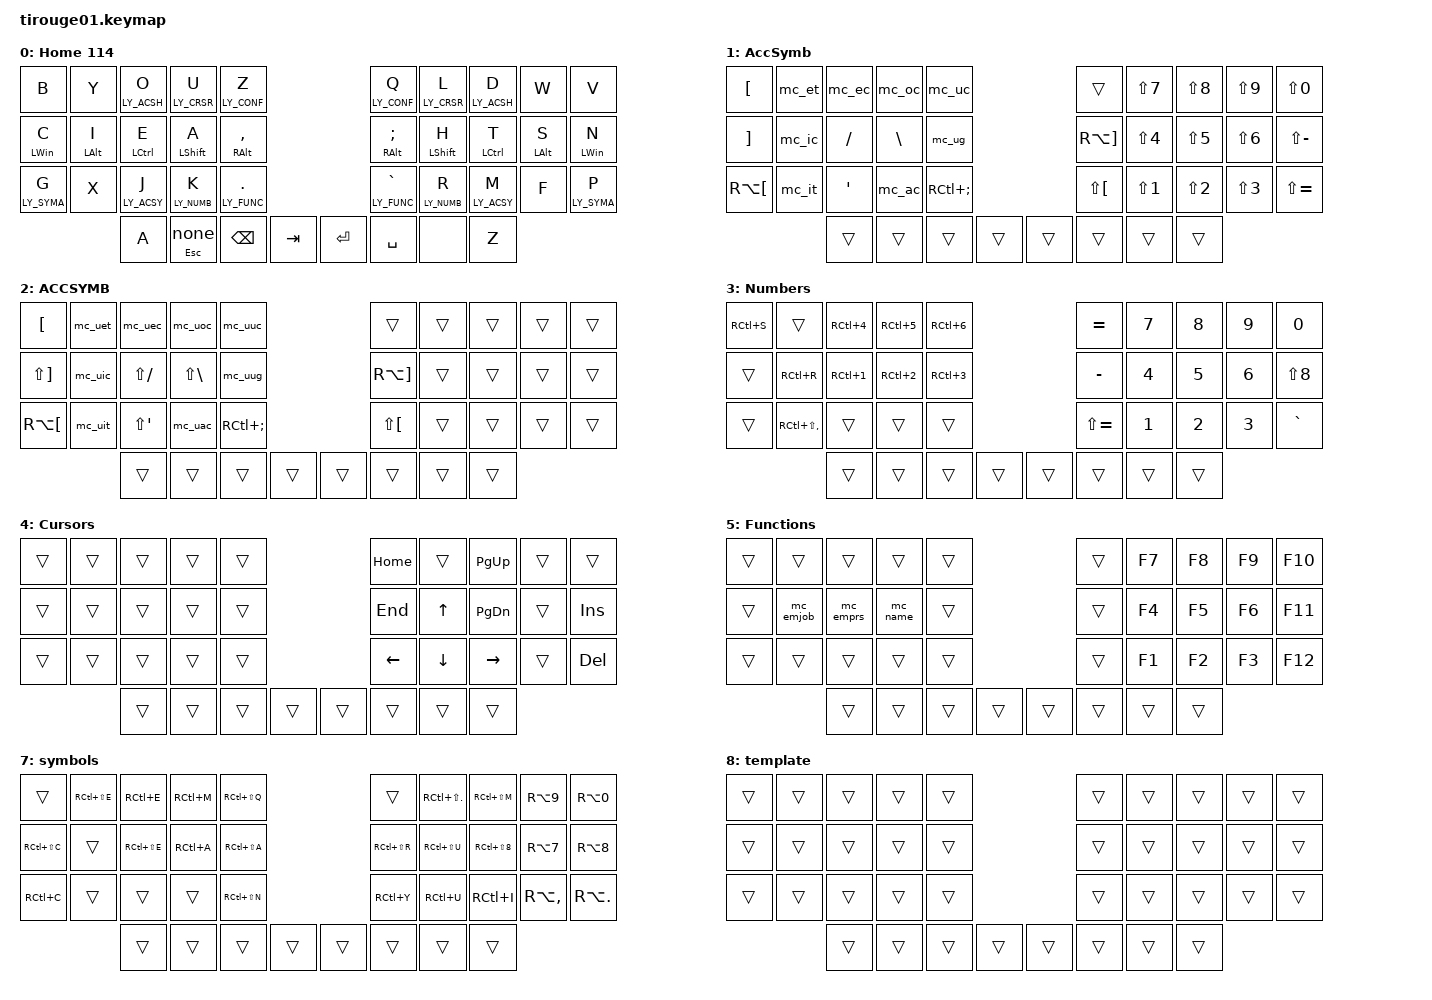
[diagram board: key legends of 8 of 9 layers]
/*
 * Copyright (c) 2022 The ZMK Contributors
 *
 * SPDX-License-Identifier: MIT
 */

#include <behaviors.dtsi>
#include <dt-bindings/zmk/keys.h>
#include <dt-bindings/zmk/bt.h>
#include <dt-bindings/zmk/outputs.h>

#define LY_DEFT 0 // Default layer.
#define LY_ACSY 1 // Accent & Symbols layer.
#define LY_ACSH 2 // Accent & Symbols shifted layer.
#define LY_NUMB 3 // Numbers layer.
#define LY_CRSR 4 // Cursor layer.
#define LY_FUNC 5 // Function layer.
#define LY_CONF 6 // Configuration layer.
#define LY_SYMA 7 // Symbols Group A layer
#define LY_TMPL 8 // Template layer.

#define TIMING_CONFIG 990 // Timing for configuration layer for the "hold/layer" related actions.
#define TIMING_PINKY  220 // Timing for pinky finger for the "hold/layer" related actions.
#define TIMING_RING   220 // Timing for ring finger for the "hold/layer" related actions.
#define TIMING_MIDDLE 200 // Timing for middle finger for the "hold/layer" related actions.
#define TIMING_INDEX  200 // Timing for index finger for the "hold/layer" related actions.
#define TIMING_THUMB  400 // Timing for thumb finger on which I am accidentally pressing too often.

// https://zmk.dev/docs/keymaps/behaviors/sticky-layer
//
// ...
// By default, sticky layers stay pressed for a second if you don't press any other key.
// You can configure this with the release-after-ms setting (see below).
// ...
&sl {
    release-after-ms = <5000>;
    ignore-modifiers;
};


/ {
    behaviors {
        ht_p: hold_tap_pinky_finger {
            compatible = "zmk,behavior-hold-tap";
            #binding-cells = <2>;
            flavor = "balanced";
            tapping-term-ms = <TIMING_PINKY>;
            quick-tap-ms = <175>;
            require-prior-idle-ms = <150>;
            bindings = <&kp>, <&kp>;
        };

        ht_r: hold_tap_ring_finger {
            compatible = "zmk,behavior-hold-tap";
            #binding-cells = <2>;
            flavor = "balanced";
            tapping-term-ms = <TIMING_RING>;
            quick-tap-ms = <175>;
            require-prior-idle-ms = <150>;
            bindings = <&kp>, <&kp>;
        };

        ht_m: hold_tap_middle_finger {
            compatible = "zmk,behavior-hold-tap";
            #binding-cells = <2>;
            flavor = "balanced";
            tapping-term-ms = <TIMING_MIDDLE>;
            quick-tap-ms = <175>;
            require-prior-idle-ms = <150>;
            bindings = <&kp>, <&kp>;
        };

        ht_i: hold_tap_index_finger {
            compatible = "zmk,behavior-hold-tap";
            #binding-cells = <2>;
            flavor = "balanced";
            tapping-term-ms = <TIMING_INDEX>;
            quick-tap-ms = <175>;
            require-prior-idle-ms = <150>;
            bindings = <&kp>, <&kp>;
        };

        ht_t: hold_tap_thumb_finger {
            compatible = "zmk,behavior-hold-tap";
            #binding-cells = <2>;
            flavor = "balanced";
            tapping-term-ms =  <TIMING_THUMB>;
            quick-tap-ms = <175>;
            require-prior-idle-ms = <150>;
            bindings = <&kp>, <&none>;
        };

        lt_c: layer_tap_config_long_timing {
            compatible = "zmk,behavior-hold-tap";
            #binding-cells = <2>;
            flavor = "balanced";
            tapping-term-ms = <TIMING_CONFIG>;
            quick-tap-ms = <175>;
            require-prior-idle-ms = <150>;
            bindings = <&mo>, <&kp>;
        };

        lt_p: layer_tap_pinky_finger {
            compatible = "zmk,behavior-hold-tap";
            #binding-cells = <2>;
            flavor = "balanced";
            tapping-term-ms = <TIMING_PINKY>;
            quick-tap-ms = <175>;
            require-prior-idle-ms = <150>;
            bindings = <&mo>, <&kp>;
        };

        lt_r: layer_tap_ring_finger {
            compatible = "zmk,behavior-hold-tap";
            #binding-cells = <2>;
            flavor = "balanced";
            tapping-term-ms = <TIMING_RING>;
            quick-tap-ms = <175>;
            require-prior-idle-ms = <150>;
            bindings = <&mo>, <&kp>;
        };

        lt_m: layer_tap_middle_finger {
            compatible = "zmk,behavior-hold-tap";
            #binding-cells = <2>;
            flavor = "balanced";
            tapping-term-ms = <TIMING_MIDDLE>;
            quick-tap-ms = <175>;
            require-prior-idle-ms = <150>;
            bindings = <&mo>, <&kp>;
        };

        lt_i: layer_tap_index_finger {
            compatible = "zmk,behavior-hold-tap";
            #binding-cells = <2>;
            flavor = "balanced";
            tapping-term-ms = <TIMING_INDEX>;
            quick-tap-ms = <175>;
            require-prior-idle-ms = <150>;
            bindings = <&mo>, <&kp>;
        };

        tg_p: layer_toggle_pinky_finger {
            compatible = "zmk,behavior-hold-tap";
            #binding-cells = <2>;
            flavor = "balanced";
            tapping-term-ms = <TIMING_PINKY>;
            quick-tap-ms = <175>;
            require-prior-idle-ms = <150>;
            bindings = <&tog>, <&kp>;
        };

        tg_r: layer_toggle_ring_finger {
            compatible = "zmk,behavior-hold-tap";
            #binding-cells = <2>;
            flavor = "balanced";
            tapping-term-ms = <TIMING_RING>;
            quick-tap-ms = <175>;
            require-prior-idle-ms = <150>;
            bindings = <&tog>, <&kp>;
        };

        tg_m: layer_toggle_middle_finger {
            compatible = "zmk,behavior-hold-tap";
            #binding-cells = <2>;
            flavor = "balanced";
            tapping-term-ms = <TIMING_MIDDLE>;
            quick-tap-ms = <175>;
            require-prior-idle-ms = <150>;
            bindings = <&tog>, <&kp>;
        };

        tg_i: layer_toggle_index_finger {
            compatible = "zmk,behavior-hold-tap";
            #binding-cells = <2>;
            flavor = "balanced";
            tapping-term-ms = <TIMING_INDEX>;
            quick-tap-ms = <175>;
            require-prior-idle-ms = <150>;
            bindings = <&tog>, <&kp>;
        };

        st_i: layer_sticky_index_finger {
            compatible = "zmk,behavior-hold-tap";
            #binding-cells = <2>;
            flavor = "balanced";
            tapping-term-ms = <TIMING_INDEX>;
            quick-tap-ms = <175>;
            require-prior-idle-ms = <150>;
            bindings = <&sl>, <&kp>;
        };

        // If you wish to ensure that a layer is toggled on or off specifically,
        // rather than switching between the two states,
        // then you can do so with the toggle-mode property.
        // Define a new behavior and assign "on" or "off" to toggle-mode.
        // https://zmk.dev/docs/keymaps/behaviors/layers#configuration
        gltog_on: toggle_layer_on_only {
            compatible = "zmk,behavior-toggle-layer";
            #binding-cells = <1>;
            display-name = "Toggle Layer On";
            toggle-mode = "on";
        };

        gltog_off: toggle_layer_off_only {
            compatible = "zmk,behavior-toggle-layer";
            #binding-cells = <1>;
            display-name = "Toggle Layer Off";
            toggle-mode = "off";
        };

        // A tap-dance key invokes a different behavior (e.g. kp) corresponding to how many times it is pressed.
        // https://zmk.dev/docs/keymaps/behaviors/tap-dance
        td_menus: tap_dance_popup_main_menus {
            compatible = "zmk,behavior-tap-dance";
            #binding-cells = <0>;
            tapping-term-ms = <200>;
            bindings = <&mc_contextcursor>, <&mc_mainmenucursor>;
        };
    };

    macros {
        // Macro to open the context menu, scroll to the first item and switch to the cursor layer.
        mc_contextcursor: macro_contextcursor {
            compatible = "zmk,behavior-macro";
            #binding-cells = <0>;
            wait-ms = <10>;
            bindings = <&kp K_CONTEXT_MENU &kp DOWN &gltog_on LY_CRSR>;
        };

        // Macro to open the main menu, scroll to the first item and switch to the cursor layer.
        mc_mainmenucursor: macro_mainmenucursor {
            compatible = "zmk,behavior-macro";
            #binding-cells = <0>;
            wait-ms = <10>;
            bindings = <&kp LALT &kp DOWN &gltog_on LY_CRSR>;
        };

        // Macro to exit the cursor layer and press enter to launch the selected item.
        mc_enterexitpopup: macro_enterexitpopup {
            compatible = "zmk,behavior-macro";
            #binding-cells = <0>;
            wait-ms = <10>;
            bindings = <&gltog_off LY_CRSR &kp KP_ENTER>;
        };

        // â
        mc_ac: macro_a_circumflex {
            compatible = "zmk,behavior-macro";
            #binding-cells = <0>;
            wait-ms = <10>;
            bindings = <&kp LBKT &kp A>;
        };

        // ê
        mc_ec: macro_e_circumflex {
            compatible = "zmk,behavior-macro";
            #binding-cells = <0>;
            wait-ms = <10>;
            bindings = <&kp LBKT &kp E>;
        };

        // ë
        mc_et: macro_e_trema {
            compatible = "zmk,behavior-macro";
            #binding-cells = <0>;
            wait-ms = <10>;
            bindings = <&kp LS(LBKT) &kp E>;
        };

        // î
        mc_ic: macro_i_circumflex {
            compatible = "zmk,behavior-macro";
            #binding-cells = <0>;
            wait-ms = <10>;
            bindings = <&kp LBKT &kp I>;
        };

        // ï
        mc_it: macro_i_trema {
            compatible = "zmk,behavior-macro";
            #binding-cells = <0>;
            wait-ms = <10>;
            bindings = <&kp LS(LBKT) &kp I>;
        };

        // í
        mc_ia: macro_i_acute {
            compatible = "zmk,behavior-macro";
            #binding-cells = <0>;
            wait-ms = <10>;
            bindings = <&kp RC(SEMI) &kp I>;
        };

        // ú
        mc_ua: macro_u_acute {
            compatible = "zmk,behavior-macro";
            #binding-cells = <0>;
            wait-ms = <10>;
            bindings = <&kp RC(SEMI) &kp U>;
        };

        // ô
        mc_oc: macro_o_circumflex {
            compatible = "zmk,behavior-macro";
            #binding-cells = <0>;
            wait-ms = <10>;
            bindings = <&kp LBKT &kp O>;
        };

        // ù
        mc_ug: macro_u_grave {
            compatible = "zmk,behavior-macro";
            #binding-cells = <0>;
            wait-ms = <10>;
            bindings = <&kp RA(LBKT) &kp U>;
        };

        // û
        mc_uc: macro_u_circumflex {
            compatible = "zmk,behavior-macro";
            #binding-cells = <0>;
            wait-ms = <10>;
            bindings = <&kp LBKT &kp U>;
        };

        // ü
        mc_ut: macro_u_trema {
            compatible = "zmk,behavior-macro";
            #binding-cells = <0>;
            wait-ms = <10>;
            bindings = <&kp LS(LBKT) &kp U>;
        };

        // Â
        mc_uac: macro_ua_circumflex {
            compatible = "zmk,behavior-macro";
            #binding-cells = <0>;
            wait-ms = <10>;
            bindings = <&kp LBKT &kp LS(A)>;
        };

        // Ê
        mc_uec: macro_ue_circumflex {
            compatible = "zmk,behavior-macro";
            #binding-cells = <0>;
            wait-ms = <10>;
            bindings = <&kp LBKT &kp LS(E)>;
        };

        // Ë
        mc_uet: macro_ue_trema {
            compatible = "zmk,behavior-macro";
            #binding-cells = <0>;
            wait-ms = <10>;
            bindings = <&kp LS(LBKT) &kp LS(E)>;
        };

        // Î
        mc_uic: macro_ui_circumflex {
            compatible = "zmk,behavior-macro";
            #binding-cells = <0>;
            wait-ms = <10>;
            bindings = <&kp LBKT &kp LS(I)>;
        };

        // Ï
        mc_uit: macro_ui_trema {
            compatible = "zmk,behavior-macro";
            #binding-cells = <0>;
            wait-ms = <10>;
            bindings = <&kp LS(LBKT) &kp LS(I)>;
        };

        // Í
        mc_uia: macro_ui_acute {
            compatible = "zmk,behavior-macro";
            #binding-cells = <0>;
            wait-ms = <10>;
            bindings = <&kp RC(SEMI) &kp LS(I)>;
        };

        // Ú
        mc_uua: macro_uu_acute {
            compatible = "zmk,behavior-macro";
            #binding-cells = <0>;
            wait-ms = <10>;
            bindings = <&kp RC(SEMI) &kp LS(U)>;
        };

        // Ô
        mc_uoc: macro_uo_circumflex {
            compatible = "zmk,behavior-macro";
            #binding-cells = <0>;
            wait-ms = <10>;
            bindings = <&kp LBKT &kp LS(O)>;
        };

        // Ù
        mc_uug: macro_uu_grave {
            compatible = "zmk,behavior-macro";
            #binding-cells = <0>;
            wait-ms = <10>;
            bindings = <&kp RA(LBKT) &kp LS(U)>;
        };

        // Û
        mc_uuc: macro_uu_circumflex {
            compatible = "zmk,behavior-macro";
            #binding-cells = <0>;
            wait-ms = <10>;
            bindings = <&kp LBKT &kp LS(U)>;
        };

        // Ü
        mc_uut: macro_uu_trema {
            compatible = "zmk,behavior-macro";
            #binding-cells = <0>;
            wait-ms = <10>;
            bindings = <&kp LS(LBKT) &kp LS(U)>;
        };

        mc_emprs: macro_email_perso {
            compatible = "zmk,behavior-macro";
            #binding-cells = <0>;
            wait-ms = <10>;
            bindings = <
                &kp D &kp E &kp N &kp I &kp S
                &kp DOT
                &kp B &kp I &kp S &kp S &kp O &kp N
                &kp AT
                &kp D &kp E &kp N &kp I &kp S &kp B &kp I &kp S &kp S &kp O &kp N
                &kp DOT
                &kp C &kp O &kp M
            >;
        };
        
        mc_emjob: macro_email_job {
            compatible = "zmk,behavior-macro";
            #binding-cells = <0>;
            wait-ms = <10>;
            bindings = <
                &kp D &kp E &kp N &kp I &kp S
                &kp DOT
                &kp B &kp I &kp S &kp S &kp O &kp N
                &kp AT
                &kp B &kp L &kp U &kp B &kp E &kp R &kp I
                &kp DOT
                &kp C &kp O &kp M
            >;
        };

        mc_name: macro_myname {
            compatible = "zmk,behavior-macro";
            #binding-cells = <0>;
            wait-ms = <10>;
            bindings = <
                &kp LS(D) &kp E &kp N &kp I &kp S
                &kp SPACE
                &kp LS(B) &kp I &kp S &kp S &kp O &kp N
            >;
        };
    };

    keymap {
        compatible = "zmk,keymap";

// | SW6  | SW7  | SW1  | SW2  | SW3  | SW4  | SW5  |                    | SW5  | SW4  | SW3  | SW2  | SW1  | SW7  | SW6  |
// | SW13 | SW14 | SW8  | SW9  | SW10 | SW11 | SW12 |                    | SW12 | SW11 | SW10 | SW9  | SW8  | SW14 | SW13 |
// | SW20 | SW21 | SW15 | SW16 | SW17 | SW18 | SW19 |                    | SW19 | SW18 | SW17 | SW16 | SW15 | SW21 | SW20 |
// | SW28 | SW29 | SW23 | SW24 | SW25 | SW26 | SW27 |                    | SW27 | SW26 | SW25 | SW24 | SW23 | SW29 | SW28 |
//                      | SW31 | SW32 | SW33 | SW34 | SW38 |      | SW38 | SW34 | SW33 | SW32 | SW31 |
//                      | SW35 | SW36 | SW37 |                                  | SW37 | SW36 | SW35 |
//
// *********************
// * 0 - BASE + LAYERS *
// *********************
// ╔═══════╦═══════╦═══════╦═══════╦═══════╗             ╔═══════╦═══════╦═══════╦═══════╦═══════╗
// ║   b   ║   y   ║   o   ║   u   ║   z   ║             ║   q   ║   l   ║   d   ║   w   ║   v   ║
// ║       ║       ║ ACCSH ║CURSORS║ CONF  ║             ║ CONF  ║CURSORS║ ACCSH ║       ║       ║
// ╠═══════╬═══════╬═══════╬═══════╬═══════╣             ╠═══════╬═══════╬═══════╬═══════╬═══════╣
// ║   c   ║   i   ║   e   ║   a   ║   ,   ║             ║   ;   ║   h   ║   t   ║   s   ║   n   ║
// ║ LWIN  ║ LALT  ║ LCTRL ║ SHIFT ║ RALT  ║             ║ RALT  ║ SHIFT ║ LCTRL ║ LALT  ║  LWIN ║
// ╠═══════╬═══════╬═══════╬═══════╬═══════╣             ╠═══════╬═══════╬═══════╬═══════╬═══════╣
// ║   g   ║   x   ║   j   ║   k   ║   .   ║             ║   /   ║   r   ║   m   ║   f   ║   p   ║
// ║ SYMBA ║       ║ ACCSY ║ NUMBR ║ FUNCT ║             ║ FUNCT ║ NUMBR ║ ACCSY ║       ║ SYMBA ║
// ╚═══════╩═══════╩═══════╩═══════╩═══════╝             ╚═══════╩═══════╩═══════╩═══════╩═══════╝
//                     ╔═══════╦═══════╦═══════╗     ╔═══════╦═══════╦═══════╗
//                     ║  ESC  ║ BACK  ║  TAB  ║     ║ ENTER ║ SPACE ║       ║
//                     ╚═══════╩═══════╩═══════╝     ╚═══════╩═══════╩═══════╝
//
        layer_0 { // Home
            display-name = "Home 114";
            bindings = <
&kp  B           &kp Y         &lt_m LY_ACSH O  &lt_i LY_CRSR U  &lt_i LY_CONF Z                              &lt_i LY_CONF Q     &lt_i LY_CRSR L &lt_m LY_ACSH D  &kp W        &kp V
&ht_p LWIN C     &ht_r LALT I  &ht_m LCTRL E    &ht_i LSHFT A    &ht_i RALT COMMA                             &ht_i RALT SEMI     &ht_i LSHFT H   &ht_m LCTRL T    &ht_r LALT S &ht_p LWIN N
&lt_p LY_SYMA G  &kp X         &lt_m LY_ACSY J  &lt_i LY_NUMB K  &st_i LY_FUNC PERIOD                         &st_i LY_FUNC GRAVE &lt_i LY_NUMB R &lt_m LY_ACSY M  &kp F        &lt_p LY_SYMA P
                               &kp A            &ht_t ESC 0      &kp BSPC              &kp TAB     &kp ENTER  &kp SPACE           &none           &kp Z
            >;

            sensor-bindings = <
                &inc_dec_kp LEFT_ARROW RIGHT_ARROW
                &inc_dec_kp UP_ARROW DOWN_ARROW
            >;

        };


// **************************************
// * 1 : LY_ACSY - ACCENT & SYMBOLS *
// **************************************
// ╔═══════╦═══════╦═══════╦═══════╦═══════╗             ╔═══════╦═══════╦═══════╦═══════╦═══════╗
// ║   ^   ║   ë   ║   ê   ║   ô   ║   û   ║             ║       ║   &   ║   *   ║   (   ║   )   ║
// ╠═══════╬═══════╬═══════╬═══════╬═══════╣             ╠═══════╬═══════╬═══════╬═══════╬═══════╣
// ║   ç   ║   î   ║   é   ║   à   ║   ù   ║             ║   ~   ║   $   ║   %   ║   ?   ║   _   ║
// ╠═══════╬═══════╬═══════╬═══════╬═══════╣             ╠═══════╬═══════╬═══════╬═══════╬═══════╣
// ║   `   ║   ï   ║   è   ║   â   ║   ´   ║             ║   ¨   ║   !   ║   @   ║   #   ║   +   ║
// ╚═══════╩═══════╩═══════╩═══════╩═══════╝             ╚═══════╩═══════╩═══════╩═══════╩═══════╝
//                     ╔═══════╦═══════╦═══════╗     ╔═══════╦═══════╦═══════╗
//                     ║       ║       ║       ║     ║       ║       ║       ║
//                     ╚═══════╩═══════╩═══════╝     ╚═══════╩═══════╩═══════╝
//
        layer_1 {
            display-name = "AccSymb";
            bindings = <
&kp LBKT      &mc_et  &mc_ec    &mc_oc    &mc_uc                          &trans        &kp LS(N7)  &kp LS(N8)  &kp LS(N9)  &kp LS(N0)
&kp RBKT      &mc_ic  &kp FSLH  &kp BSLH  &mc_ug                          &kp RA(RBKT)  &kp LS(N4)  &kp LS(N5)  &kp LS(N6)  &kp LS(MINUS)
&kp RA(LBKT)  &mc_it  &kp APOS  &mc_ac    &kp RC(SEMI)                    &kp LS(LBKT)  &kp LS(N1)  &kp LS(N2)  &kp LS(N3)  &kp LS(EQUAL)
                      &trans    &trans    &trans       &trans     &trans  &trans        &trans      &trans
            >;
        };

// **********************************************
// * 2 : LY_ACSH - ACCENT & SYMBOLS SHIFTED *
// **********************************************
// ╔═══════╦═══════╦═══════╦═══════╦═══════╗             ╔═══════╦═══════╦═══════╦═══════╦═══════╗
// ║   ^   ║   Ë   ║   Ê   ║   Ô   ║   Û   ║             ║       ║       ║       ║       ║       ║
// ╠═══════╬═══════╬═══════╬═══════╬═══════╣             ╠═══════╬═══════╬═══════╬═══════╬═══════╣
// ║   Ç   ║   Î   ║   É   ║   À   ║   Ù   ║             ║   ~   ║       ║       ║       ║       ║
// ╠═══════╬═══════╬═══════╬═══════╬═══════╣             ╠═══════╬═══════╬═══════╬═══════╬═══════╣
// ║   `   ║   Ï   ║   È   ║   Â   ║   ´   ║             ║   ¨   ║       ║       ║       ║       ║
// ╚═══════╩═══════╩═══════╩═══════╩═══════╝             ╚═══════╩═══════╩═══════╩═══════╩═══════╝
//                     ╔═══════╦═══════╦═══════╗     ╔═══════╦═══════╦═══════╗
//                     ║       ║       ║       ║     ║       ║       ║       ║
//                     ╚═══════╩═══════╩═══════╝     ╚═══════╩═══════╩═══════╝
//
        layer_2 {
            display-name = "ACCSYMB";
            bindings = <
&kp LBKT      &mc_uet  &mc_uec       &mc_uoc       &mc_uuc                          &trans        &trans  &trans  &trans  &trans
&kp LS(RBKT)  &mc_uic  &kp LS(FSLH)  &kp LS(BSLH)  &mc_uug                          &kp RA(RBKT)  &trans  &trans  &trans  &trans
&kp RA(LBKT)  &mc_uit  &kp LS(APOS)  &mc_uac       &kp RC(SEMI)                     &kp LS(LBKT)  &trans  &trans  &trans  &trans
                       &trans        &trans        &trans        &trans     &trans  &trans        &trans  &trans
            >;
        };

// ****************************
// * 3 : LY_NUMB - NUMBERS *
// ****************************
// ╔═══════╦═══════╦═══════╦═══════╦═══════╗             ╔═══════╦═══════╦═══════╦═══════╦═══════╗
// ║   ß   ║       ║   ¼   ║   ½   ║   ¾   ║             ║   =   ║   7   ║   8   ║   9   ║   0   ║
// ╠═══════╬═══════╬═══════╬═══════╬═══════╣             ╠═══════╬═══════╬═══════╬═══════╬═══════╣
// ║       ║   ¶   ║   ¹   ║   ²   ║   ³   ║             ║   -   ║   4   ║   5   ║   6   ║   *   ║
// ╠═══════╬═══════╬═══════╬═══════╬═══════╣             ╠═══════╬═══════╬═══════╬═══════╬═══════╣
// ║       ║   ×   ║       ║       ║       ║             ║   +   ║   1   ║   2   ║   3   ║   /   ║
// ╚═══════╩═══════╩═══════╩═══════╩═══════╝             ╚═══════╩═══════╩═══════╩═══════╩═══════╝
//                     ╔═══════╦═══════╦═══════╗     ╔═══════╦═══════╦═══════╗
//                     ║       ║       ║       ║     ║       ║       ║       ║
//                     ╚═══════╩═══════╩═══════╝     ╚═══════╩═══════╩═══════╝
//
        layer_3 {
            display-name = "Numbers";
            bindings = <
&kp RC(S)  &trans             &kp RC(N4)  &kp RC(N5)  &kp RC(N6)                &kp EQUAL      &kp N7  &kp N8  &kp N9  &kp N0
&trans     &kp RC(R)          &kp RC(N1)  &kp RC(N2)  &kp RC(N3)                &kp MINUS      &kp N4  &kp N5  &kp N6  &kp LS(N8)
&trans     &kp RC(LS(COMMA))  &trans      &trans      &trans                    &kp LS(EQUAL)  &kp N1  &kp N2  &kp N3  &kp GRAVE
                              &trans      &trans      &trans  &trans    &trans  &trans         &trans  &trans
             >;
        };

// ****************************
// * 4 : LY_CRSR - CURSORS *
// ****************************
// ╔═══════╦═══════╦═══════╦═══════╦═══════╗             ╔═══════╦═══════╦═══════╦═══════╦═══════╗
// ║       ║       ║       ║       ║       ║             ║ home  ║       ║ pgup  ║       ║       ║
// ╠═══════╬═══════╬═══════╬═══════╬═══════╣             ╠═══════╬═══════╬═══════╬═══════╬═══════╣
// ║       ║       ║       ║       ║       ║             ║  end  ║   ↑   ║ pgdwn ║       ║  ins  ║
// ╠═══════╬═══════╬═══════╬═══════╬═══════╣             ╠═══════╬═══════╬═══════╬═══════╬═══════╣
// ║       ║       ║       ║       ║       ║             ║   ←   ║   ↓   ║   →   ║       ║  del  ║
// ╚═══════╩═══════╩═══════╩═══════╩═══════╝             ╚═══════╩═══════╩═══════╩═══════╩═══════╝
//                     ╔═══════╦═══════╦═══════╗     ╔═══════╦═══════╦═══════╗
//                     ║       ║       ║       ║     ║       ║       ║       ║
//                     ╚═══════╩═══════╩═══════╝     ╚═══════╩═══════╩═══════╝
//
        layer_4 {
            display-name = "Cursors";
            bindings = <
&trans  &trans  &trans  &trans  &trans                    &kp HOME  &trans    &kp PG_UP  &trans  &trans
&trans  &trans  &trans  &trans  &trans                    &kp END   &kp UP    &kp PG_DN  &trans  &kp INS
&trans  &trans  &trans  &trans  &trans                    &kp LEFT  &kp DOWN  &kp RIGHT  &trans  &kp DEL
                &trans  &trans  &trans  &trans    &trans  &trans    &trans    &trans
            >;
        };

// ********************************
// * 5 : LY_FUNC - FUNCTIONS *
// ********************************
// ╔═══════╦═══════╦═══════╦═══════╦═══════╗             ╔═══════╦═══════╦═══════╦═══════╦═══════╗
// ║       ║       ║       ║       ║       ║             ║       ║   F7  ║   F8  ║   F9  ║  F10  ║
// ╠═══════╬═══════╬═══════╬═══════╬═══════╣             ╠═══════╬═══════╬═══════╬═══════╬═══════╣
// ║       ║ db@bl ║ db@db ║ Denis ║       ║             ║       ║   F4  ║   F5  ║   F6  ║  F11  ║
// ╠═══════╬═══════╬═══════╬═══════╬═══════╣             ╠═══════╬═══════╬═══════╬═══════╬═══════╣
// ║       ║       ║       ║       ║       ║             ║       ║   F1  ║   F2  ║   F3  ║  F12  ║
// ╚═══════╩═══════╩═══════╩═══════╩═══════╝             ╚═══════╩═══════╩═══════╩═══════╩═══════╝
//                     ╔═══════╦═══════╦═══════╗     ╔═══════╦═══════╦═══════╗
//                     ║       ║       ║       ║     ║       ║       ║       ║
//                     ╚═══════╩═══════╩═══════╝     ╚═══════╩═══════╩═══════╝
//
        layer_5 {
            display-name = "Functions";
            bindings = <
&trans  &trans     &trans     &trans    &trans                   &trans  &kp F7  &kp F8  &kp F9  &kp F10
&trans  &mc_emjob  &mc_emprs  &mc_name  &trans                   &trans  &kp F4  &kp F5  &kp F6  &kp F11
&trans  &trans     &trans     &trans    &trans                   &trans  &kp F1  &kp F2  &kp F3  &kp F12
                   &trans     &trans    &trans  &trans    &trans &trans  &trans  &trans
            >;
        };

// *******************************
// * 6 : LY_CONF - CONFIGURATION *
// *******************************
// ╔═══════╦═══════╦═══════╦═══════╦═══════╗             ╔═══════╦═══════╦═══════╦═══════╦═══════╗
// ║       ║       ║       ║       ║ BTLDR ║             ║ BTLDR ║       ║       ║       ║  BT0  ║
// ╠═══════╬═══════╬═══════╬═══════╬═══════╣             ╠═══════╬═══════╬═══════╬═══════╬═══════╣
// ║       ║       ║       ║       ║  OFF  ║             ║  OFF  ║  BT4  ║       ║       ║       ║
// ╠═══════╬═══════╬═══════╬═══════╬═══════╣             ╠═══════╬═══════╬═══════╬═══════╬═══════╣
// ║       ║       ║       ║       ║       ║             ║ BTCLR ║  BT1  ║  BT2  ║  BT3  ║       ║
// ╚═══════╩═══════╩═══════╩═══════╩═══════╝             ╚═══════╩═══════╩═══════╩═══════╩═══════╝
//                     ╔═══════╦═══════╦═══════╗     ╔═══════╦═══════╦═══════╗
//                     ║       ║       ║       ║     ║       ║       ║       ║
//                     ╚═══════╩═══════╩═══════╝     ╚═══════╩═══════╩═══════╝
//
        layer_6 {
            display-name = "config";
            bindings = <
&trans  &trans  &trans  &trans  &bootloader                    &bootloader     &trans        &trans        &trans        &bt BT_SEL 0        
&trans  &trans  &trans  &trans  &soft_off                      &soft_off       &bt BT_SEL 4  &trans        &trans        &trans
&trans  &trans  &trans  &trans  &trans                         &bt BT_CLR_ALL  &bt BT_SEL 1  &bt BT_SEL 2  &bt BT_SEL 3  &trans
                &trans  &trans  &trans       &trans    &trans  &trans          &trans        &trans        &trans        &trans
            >;
        };

// *********************************
// * 7 : LY_SYMA - SYMBOLS GROUP A *
// *********************************
// ╔═══════╦═══════╦═══════╦═══════╦═══════╗             ╔═══════╦═══════╦═══════╦═══════╦═══════╗
// ║       ║   Œ   ║   œ   ║   µ   ║   Ω   ║             ║       ║   ÷   ║   º   ║   [   ║   ]   ║
// ╠═══════╬═══════╬═══════╬═══════╬═══════╣             ╠═══════╬═══════╬═══════╬═══════╬═══════╣
// ║   ©   ║       ║   €   ║   æ   ║   Æ   ║             ║   ®   ║   ↑   ║   ™   ║   {   ║   }   ║
// ╠═══════╬═══════╬═══════╬═══════╬═══════╣             ╠═══════╬═══════╬═══════╬═══════╬═══════╣
// ║   ¢   ║       ║       ║       ║   ♪   ║             ║   ←   ║   ↓   ║   →   ║   <   ║   >   ║
// ╚═══════╩═══════╩═══════╩═══════╩═══════╝             ╚═══════╩═══════╩═══════╩═══════╩═══════╝
//                     ╔═══════╦═══════╦═══════╗     ╔═══════╦═══════╦═══════╗
//                     ║       ║       ║       ║     ║       ║       ║       ║
//                     ╚═══════╩═══════╩═══════╝     ╚═══════╩═══════╩═══════╝
//
        layer_7 {
            display-name = "symbols";
            bindings = <
&trans        &kp RC(LS(E)) &kp RC(E)     &kp RC(M)  &kp RC(LS(Q))            &trans         &kp RC(LS(PERIOD)) &kp RC(LS(M))  &kp RA(N9)    &kp RA(N0)
&kp RC(LS(C)) &trans        &kp RC(LS(E)) &kp RC(A)  &kp RC(LS(A))            &kp RC(LS(R))  &kp RC(LS(U))      &kp RC(LS(N8)) &kp RA(N7)    &kp RA(N8)
&kp RC(C)     &trans        &trans        &trans     &kp RC(LS(N))            &kp RC(Y)      &kp RC(U)          &kp RC(I)      &kp RA(COMMA) &kp RA(PERIOD)
                            &trans        &trans     &trans        &trans     &trans         &trans             &trans         &trans
                >;
        };


// ******************************
// * 8 : LY_TMPL - TEMPLATE *
// ******************************
//
// ╔═══════╦═══════╦═══════╦═══════╦═══════╗             ╔═══════╦═══════╦═══════╦═══════╦═══════╗
// ║       ║       ║       ║       ║       ║             ║       ║       ║       ║       ║       ║
// ╠═══════╬═══════╬═══════╬═══════╬═══════╣             ╠═══════╬═══════╬═══════╬═══════╬═══════╣
// ║       ║       ║       ║       ║       ║             ║       ║       ║       ║       ║       ║
// ╠═══════╬═══════╬═══════╬═══════╬═══════╣             ╠═══════╬═══════╬═══════╬═══════╬═══════╣
// ║       ║       ║       ║       ║       ║             ║       ║       ║       ║       ║       ║
// ╚═══════╩═══════╩═══════╩═══════╩═══════╝             ╚═══════╩═══════╩═══════╩═══════╩═══════╝
//                     ╔═══════╦═══════╦═══════╗     ╔═══════╦═══════╦═══════╗
//                     ║       ║       ║       ║     ║       ║       ║       ║
//                     ╚═══════╩═══════╩═══════╝     ╚═══════╩═══════╩═══════╝
        layer_8 {
            display-name = "template";
            bindings = <
&trans &trans &trans &trans &trans                   &trans &trans &trans &trans &trans
&trans &trans &trans &trans &trans                   &trans &trans &trans &trans &trans
&trans &trans &trans &trans &trans                   &trans &trans &trans &trans &trans
              &trans &trans &trans &trans     &trans &trans &trans &trans
            >;
        };

    }; // keymap
};
